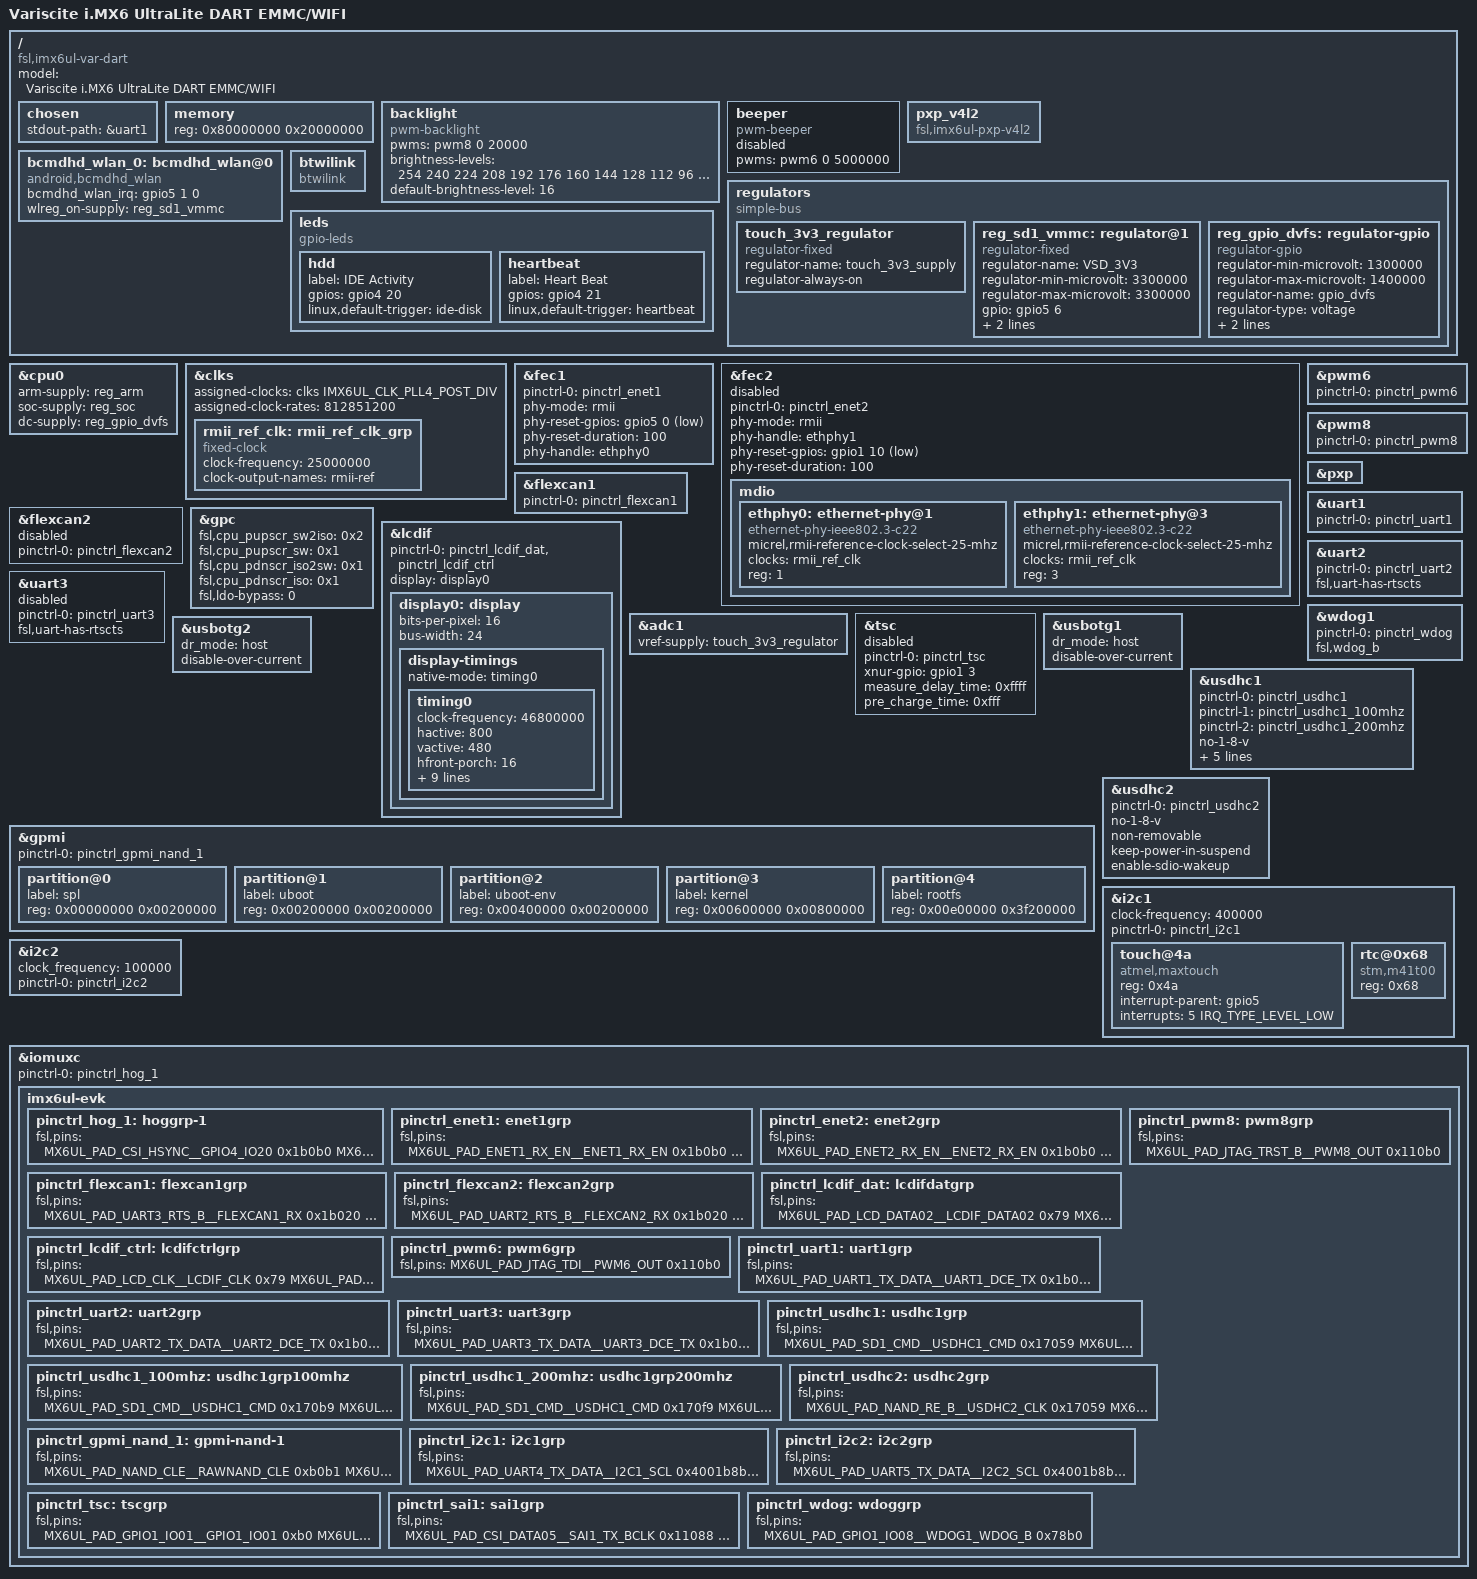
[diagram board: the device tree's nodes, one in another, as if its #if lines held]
/*
 * Copyright (C) 2015 Freescale Semiconductor, Inc.
 *
 * Copyright (C) 2015-2016 Variscite Ltd. - http://www.variscite.com
 *
 * This program is free software; you can redistribute it and/or modify
 * it under the terms of the GNU General Public License version 2 as
 * published by the Free Software Foundation.
 */
/* #define WIFI */
/* #define EMMC */
/* #define  NAND  */
/dts-v1/;

#include <dt-bindings/input/input.h>
#include "imx6ul.dtsi"

/ {
#ifdef NAND
#ifdef WIFI
	model = "Variscite i.MX6 UltraLite DART NAND/WIFI";
#else
	model = "Variscite i.MX6 UltraLite DART NAND/SD";
#endif
#endif
#ifdef EMMC
#ifdef WIFI
	model = "Variscite i.MX6 UltraLite DART EMMC/WIFI";
#else
	model = "Variscite i.MX6 UltraLite DART EMMC/SD";
#endif
#endif
	compatible = "fsl,imx6ul-var-dart", "fsl,imx6ul";

	chosen {
		stdout-path = &uart1;
	};

	memory {
		reg = <0x80000000 0x20000000>;
	};

	backlight {
		compatible = "pwm-backlight";
		pwms = <&pwm8 0 20000>;
		brightness-levels = <254 240 224 208 192 176 160 144 128 112 96 80 64 48 32 16 0>;
		default-brightness-level = <16>;
		status = "okay";
	};

	beeper {
		compatible = "pwm-beeper";
		pwms = <&pwm6 0 5000000>;
		status = "disabled";
	};

	pxp_v4l2 {
		compatible = "fsl,imx6ul-pxp-v4l2", "fsl,imx6sx-pxp-v4l2", "fsl,imx6sl-pxp-v4l2";
		status = "okay";
	};

	regulators {
		compatible = "simple-bus";
		#address-cells = <1>;
		#size-cells = <0>;

		touch_3v3_regulator: touch_3v3_regulator {
			compatible = "regulator-fixed";
			regulator-name = "touch_3v3_supply";
			regulator-always-on;
			status = "okay";
		};

#ifdef WIFI
/* force VMMC1 to always on so BT can operate independently of Wi-Fi */
		reg_sd1_vmmc: regulator@1 {
			compatible = "regulator-fixed";
			regulator-name = "VSD_3V3";
			regulator-min-microvolt = <3300000>;
			regulator-max-microvolt = <3300000>;
			gpio = <&gpio5 6 GPIO_ACTIVE_HIGH>;	/* WL_REG_ON: SNVS_TAMPER1 (gpio5_6) */
			enable-active-high;
			regulator-always-on;
		};

#endif
		reg_gpio_dvfs: regulator-gpio {
			compatible = "regulator-gpio";
			regulator-min-microvolt = <1300000>;
			regulator-max-microvolt = <1400000>;
			regulator-name = "gpio_dvfs";
			regulator-type = "voltage";
			gpios = <&gpio4 13 GPIO_ACTIVE_HIGH>;
			states = <1300000 0x1 1400000 0x0>;
		};
	};

#ifdef WIFI

	/* define hook for BCMDHD driver.   */
	/* Include WL_HOST_WAKE and WL_REG_ON GPIO's. */
	bcmdhd_wlan_0: bcmdhd_wlan@0 {
		compatible = "android,bcmdhd_wlan";
		/* WL_HOST_WAKE: ENET2_RX_ER (gpio5_01) */
		bcmdhd_wlan_irq = <&gpio5 1 0>;
		wlreg_on-supply = <&reg_sd1_vmmc>;
	};

	btwilink {
		compatible = "btwilink";
	};

#endif

	leds {
		compatible = "gpio-leds";
		hdd {
			label = "IDE Activity";
			gpios = <&gpio4 20 0>;
			linux,default-trigger = "ide-disk";
		};

		heartbeat {
			label = "Heart Beat";
			gpios = <&gpio4 21 0>;
			linux,default-trigger = "heartbeat";
		};
	};
};

&cpu0 {
	arm-supply = <&reg_arm>;
	soc-supply = <&reg_soc>;
	dc-supply = <&reg_gpio_dvfs>;
};

&clks {
	/* ref_clk for micrel ethernet phy */
	rmii_ref_clk: rmii_ref_clk_grp {
		compatible = "fixed-clock";
		#clock-cells = <0>;
		clock-frequency = <25000000>;
		clock-output-names = "rmii-ref";
	};
};

&clks {
	assigned-clocks = <&clks IMX6UL_CLK_PLL4_POST_DIV>;
	assigned-clock-rates = <812851200>;
};

&fec1 {
	pinctrl-names = "default";
	pinctrl-0 = <&pinctrl_enet1>;
	phy-mode = "rmii";
	phy-reset-gpios=<&gpio5 0 1>;
	phy-reset-duration=<100>;
	phy-handle = <&ethphy0>;
	status = "okay";
};

&fec2 {
	pinctrl-names = "default";
	pinctrl-0 = <&pinctrl_enet2>;
	phy-mode = "rmii";
	phy-handle = <&ethphy1>;
	phy-reset-gpios=<&gpio1 10 1>;
	phy-reset-duration=<100>;
	status = "disabled";
	mdio {
		#address-cells = <1>;
		#size-cells = <0>;

		ethphy0: ethernet-phy@1 {
			compatible = "ethernet-phy-ieee802.3-c22";
			micrel,rmii-reference-clock-select-25-mhz;
			clocks = <&rmii_ref_clk>;
			clock-names = "rmii-ref";
			reg = <1>;
		};

		ethphy1: ethernet-phy@3 {
			compatible = "ethernet-phy-ieee802.3-c22";
			micrel,rmii-reference-clock-select-25-mhz;
			clocks = <&rmii_ref_clk>;
			clock-names = "rmii-ref";
			reg = <3>;
		};
	};
};

&flexcan1 {
	pinctrl-names = "default";
	pinctrl-0 = <&pinctrl_flexcan1>;
	status = "okay";
};

&flexcan2 {
	pinctrl-names = "default";
	pinctrl-0 = <&pinctrl_flexcan2>;
	status = "disabled";
};

&gpc {
	fsl,cpu_pupscr_sw2iso = <0x2>;
	fsl,cpu_pupscr_sw = <0x1>;
	fsl,cpu_pdnscr_iso2sw = <0x1>;
	fsl,cpu_pdnscr_iso = <0x1>;
	fsl,ldo-bypass = <0>; /* DCDC, ldo-enable */
};

&lcdif {
	pinctrl-names = "default";
	pinctrl-0 = <&pinctrl_lcdif_dat
		     &pinctrl_lcdif_ctrl>;
	display = <&display0>;
	status = "okay";

	display0: display {
		bits-per-pixel = <16>;
		bus-width = <24>;

		display-timings {
			native-mode = <&timing0>;
			timing0: timing0 {
				clock-frequency =<46800000>;
				hactive = <800>;
				vactive = <480>;
				hfront-porch = <16>;
				hback-porch = <46>;
				hsync-len = <2>;
				vback-porch = <23>;
				vfront-porch = <7>;
				vsync-len = <2>;
				hsync-active = <0>;
				vsync-active = <0>;
				de-active = <1>;
				pixelclk-active = <0>;
			};
		};
	};
};

&pwm6 {
	pinctrl-names = "default";
	pinctrl-0 = <&pinctrl_pwm6>;
	status = "okay";
};

&pwm8 {
	pinctrl-names = "default";
	pinctrl-0 = <&pinctrl_pwm8>;
	status = "okay";
};

&pxp {
	status = "okay";
};

&adc1 {
	vref-supply = <&touch_3v3_regulator>;
	status = "okay";
};

&tsc {
	pinctrl-names = "default";
	pinctrl-0 = <&pinctrl_tsc>;
	xnur-gpio = <&gpio1 3 0>;
	measure_delay_time = <0xffff>;
	pre_charge_time = <0xfff>;
	status = "disabled";
};

/* Console Uart */
&uart1 {
	pinctrl-names = "default";
	pinctrl-0 = <&pinctrl_uart1>;
	status = "okay";
};

/* Bluetooth Uart */
&uart2 {
	pinctrl-names = "default";
	pinctrl-0 = <&pinctrl_uart2>;
	fsl,uart-has-rtscts;
	status = "okay";
};

/* ttymxc2 UART */
&uart3 {
	pinctrl-names = "default";
	pinctrl-0 = <&pinctrl_uart3>;
	fsl,uart-has-rtscts;
	status = "disabled";
};

&wdog1 {
	pinctrl-names = "default";
	pinctrl-0 = <&pinctrl_wdog>;
	fsl,wdog_b;
};

&usbotg1 {
	dr_mode = "host";
	disable-over-current;
	status = "okay";
};

&usbotg2 {
	dr_mode = "host";
	disable-over-current;
	status = "okay";
};

#ifdef WIFI
/*  Wi-Fi/BT SD Card Slot Definition */
&usdhc1 {
	pinctrl-names = "default", "state_100mhz", "state_200mhz";
	pinctrl-0 = <&pinctrl_usdhc1>;
	pinctrl-1 = <&pinctrl_usdhc1_100mhz>;
	pinctrl-2 = <&pinctrl_usdhc1_200mhz>;
	no-1-8-v;
	keep-power-in-suspend;
	enable-sdio-wakeup;
	vmmc-supply = <&reg_sd1_vmmc>;
	wifi-host;			/* add hook for SD card detect mechanism */
	non-removable;
	status = "okay";
};
#else
&usdhc1 {
	pinctrl-names = "default", "state_100mhz", "state_200mhz";
	pinctrl-0 = <&pinctrl_usdhc1>;
	pinctrl-1 = <&pinctrl_usdhc1_100mhz>;
	pinctrl-2 = <&pinctrl_usdhc1_200mhz>;
	no-1-8-v;
	keep-power-in-suspend;
	enable-sdio-wakeup;
	cd-gpios = <&gpio4 19 GPIO_ACTIVE_LOW>;
	status = "okay";
};
#endif

#ifdef NAND
&gpmi {
	pinctrl-names = "default";
	pinctrl-0 = <&pinctrl_gpmi_nand_1>;
	status = "okay";

	partition@0 {
		label = "spl";
		reg = <0x00000000 0x00200000>;
	};

	partition@1 {
		label = "uboot";
		reg = <0x00200000 0x00200000>;
	};

	partition@2 {
		label = "uboot-env";
		reg = <0x00400000 0x00200000>;
	};

	partition@3 {
		label = "kernel";
		reg = <0x00600000 0x00800000>;
	};

	partition@4 {
		label = "rootfs";
		reg = <0x00e00000 0x3f200000>;
	};
};

&usdhc2 {
	status = "disabled";
};
#endif

#ifdef EMMC
&usdhc2 {
	pinctrl-names = "default";
	pinctrl-0 = <&pinctrl_usdhc2>;
	no-1-8-v;
	non-removable;
	keep-power-in-suspend;
	enable-sdio-wakeup;
	status = "okay";
};
#endif

&i2c1 {
	clock-frequency = <400000>;
	pinctrl-names = "default";
	pinctrl-0 = <&pinctrl_i2c1>;
	status = "okay";

	/* Atmel mxt640t Touchcontroller */
	touch@4a {
                 	compatible = "atmel,maxtouch";
                 	reg = <0x4a>;
		 	interrupt-parent = <&gpio5>;
		 	interrupts = <5 IRQ_TYPE_LEVEL_LOW>;
       		};

	/* ST M41T00S RTC module */
        rtc@0x68 {
                 compatible = "stm,m41t00";
                 reg = <0x68>;
	};

};

&i2c2 {
	clock_frequency = <100000>;
	pinctrl-names = "default";
	pinctrl-0 = <&pinctrl_i2c2>;
	status = "okay";

};

&iomuxc {
	pinctrl-names = "default";
	pinctrl-0 = <&pinctrl_hog_1>;
	imx6ul-evk {
		pinctrl_hog_1: hoggrp-1 {
			fsl,pins = <
				MX6UL_PAD_CSI_HSYNC__GPIO4_IO20		0x1b0b0	/* LED 1 */
				MX6UL_PAD_CSI_DATA00__GPIO4_IO21	0x1b0b0	/* LED 2 */
				MX6UL_PAD_GPIO1_IO07__ENET2_MDC		0x1b0b0
				MX6UL_PAD_GPIO1_IO06__ENET2_MDIO	0x1b0b0
				MX6UL_PAD_SNVS_TAMPER4__GPIO5_IO04	0x1b0b0	/* BT Enable */
				MX6UL_PAD_SNVS_TAMPER0__GPIO5_IO00	0x1b0b0
				MX6UL_PAD_SNVS_TAMPER5__GPIO5_IO05 	0x1b0b0
				MX6UL_PAD_GPIO1_IO00__GPT1_CAPTURE1	0x1b0b0 /* ROTORCODESIGNAL */
				MX6UL_PAD_GPIO1_IO05__GPIO1_IO05	0x1b0b0 /* SENSE_PWR_IN */
				MX6UL_PAD_CSI_DATA01__GPIO4_IO22	0x1b0b0 /* HW_VARIANT_3 */
			>;
		};

		pinctrl_enet1: enet1grp {
			fsl,pins = <
				MX6UL_PAD_ENET1_RX_EN__ENET1_RX_EN	0x1b0b0
				MX6UL_PAD_ENET1_RX_ER__ENET1_RX_ER	0x1b0b0
				MX6UL_PAD_ENET1_RX_DATA0__ENET1_RDATA00	0x1b0b0
				MX6UL_PAD_ENET1_RX_DATA1__ENET1_RDATA01	0x1b0b0
				MX6UL_PAD_ENET1_TX_EN__ENET1_TX_EN	0x1b0b0
				MX6UL_PAD_ENET1_TX_DATA0__ENET1_TDATA00	0x1b0b0
				MX6UL_PAD_ENET1_TX_DATA1__ENET1_TDATA01	0x1b0b0
				MX6UL_PAD_ENET1_TX_CLK__ENET1_REF_CLK1	0x4001b031
			>;
		};

		pinctrl_enet2: enet2grp {
			fsl,pins = <
				MX6UL_PAD_ENET2_RX_EN__ENET2_RX_EN	0x1b0b0
				MX6UL_PAD_ENET2_RX_ER__ENET2_RX_ER	0x1b0b0
				MX6UL_PAD_ENET2_RX_DATA0__ENET2_RDATA00	0x1b0b0
				MX6UL_PAD_ENET2_RX_DATA1__ENET2_RDATA01	0x1b0b0
				MX6UL_PAD_ENET2_TX_EN__ENET2_TX_EN	0x1b0b0
				MX6UL_PAD_ENET2_TX_DATA0__ENET2_TDATA00	0x1b0b0
				MX6UL_PAD_ENET2_TX_DATA1__ENET2_TDATA01	0x1b0b0
				MX6UL_PAD_ENET2_TX_CLK__ENET2_REF_CLK2	0x4001b031
				MX6UL_PAD_JTAG_MOD__GPIO1_IO10		0x1b0b0
			>;
		};

		pinctrl_flexcan1: flexcan1grp{
			fsl,pins = <
				MX6UL_PAD_UART3_RTS_B__FLEXCAN1_RX	0x1b020
				MX6UL_PAD_UART3_CTS_B__FLEXCAN1_TX	0x1b020
			>;
		};

		pinctrl_flexcan2: flexcan2grp{
			fsl,pins = <
				MX6UL_PAD_UART2_RTS_B__FLEXCAN2_RX	0x1b020
				MX6UL_PAD_UART2_CTS_B__FLEXCAN2_TX	0x1b020
			>;
		};

		pinctrl_lcdif_dat: lcdifdatgrp {
			fsl,pins = <
				MX6UL_PAD_LCD_DATA02__LCDIF_DATA02	0x79
				MX6UL_PAD_LCD_DATA03__LCDIF_DATA03	0x79
				MX6UL_PAD_LCD_DATA04__LCDIF_DATA04	0x79
				MX6UL_PAD_LCD_DATA05__LCDIF_DATA05	0x79
				MX6UL_PAD_LCD_DATA06__LCDIF_DATA06	0x79
				MX6UL_PAD_LCD_DATA07__LCDIF_DATA07	0x79
				MX6UL_PAD_LCD_DATA10__LCDIF_DATA10	0x79
				MX6UL_PAD_LCD_DATA11__LCDIF_DATA11	0x79
				MX6UL_PAD_LCD_DATA12__LCDIF_DATA12	0x79
				MX6UL_PAD_LCD_DATA13__LCDIF_DATA13	0x79
				MX6UL_PAD_LCD_DATA14__LCDIF_DATA14	0x79
				MX6UL_PAD_LCD_DATA15__LCDIF_DATA15	0x79
				MX6UL_PAD_LCD_DATA18__LCDIF_DATA18	0x79
				MX6UL_PAD_LCD_DATA19__LCDIF_DATA19	0x79
				MX6UL_PAD_LCD_DATA20__LCDIF_DATA20	0x79
				MX6UL_PAD_LCD_DATA21__LCDIF_DATA21	0x79
				MX6UL_PAD_LCD_DATA22__LCDIF_DATA22	0x79
				MX6UL_PAD_LCD_DATA23__LCDIF_DATA23	0x79
			>;
		};

		pinctrl_lcdif_ctrl: lcdifctrlgrp {
			fsl,pins = <
				MX6UL_PAD_LCD_CLK__LCDIF_CLK		0x79
				MX6UL_PAD_LCD_ENABLE__LCDIF_ENABLE	0x79
			>;
		};

		pinctrl_pwm6: pwm6grp {
			fsl,pins = <
				MX6UL_PAD_JTAG_TDI__PWM6_OUT		0x110b0
			>;
		};

		pinctrl_pwm8: pwm8grp {
			fsl,pins = <
				MX6UL_PAD_JTAG_TRST_B__PWM8_OUT		0x110b0
			>;
		};

		pinctrl_uart1: uart1grp {
			fsl,pins = <
				MX6UL_PAD_UART1_TX_DATA__UART1_DCE_TX	0x1b0b1
				MX6UL_PAD_UART1_RX_DATA__UART1_DCE_RX	0x1b0b1
			>;
		};

		pinctrl_uart2: uart2grp {
			fsl,pins = <
				MX6UL_PAD_UART2_TX_DATA__UART2_DCE_TX	0x1b0b1
				MX6UL_PAD_UART2_RX_DATA__UART2_DCE_RX	0x1b0b1
				MX6UL_PAD_UART2_CTS_B__UART2_DCE_CTS	0x1b0b1
				MX6UL_PAD_UART2_RTS_B__UART2_DCE_RTS	0x1b0b1
			>;
		};

		pinctrl_uart3: uart3grp {
			fsl,pins = <
				MX6UL_PAD_UART3_TX_DATA__UART3_DCE_TX	0x1b0b1
				MX6UL_PAD_UART3_RX_DATA__UART3_DCE_RX	0x1b0b1
				MX6UL_PAD_UART3_CTS_B__UART3_DCE_CTS	0x1b0b1
				MX6UL_PAD_UART3_RTS_B__UART3_DCE_RTS	0x1b0b1
			>;
		};

		pinctrl_usdhc1: usdhc1grp {
			fsl,pins = <
				MX6UL_PAD_SD1_CMD__USDHC1_CMD		0x17059
				MX6UL_PAD_SD1_CLK__USDHC1_CLK		0x17059
				MX6UL_PAD_SD1_DATA0__USDHC1_DATA0	0x17059
				MX6UL_PAD_SD1_DATA1__USDHC1_DATA1	0x17059
				MX6UL_PAD_SD1_DATA2__USDHC1_DATA2	0x17059
				MX6UL_PAD_SD1_DATA3__USDHC1_DATA3	0x17059
				MX6UL_PAD_CSI_VSYNC__GPIO4_IO19		0x1b0b1	/* SD card detect */
				MX6UL_PAD_SNVS_TAMPER6__GPIO5_IO06	0x03029	/* WLAN enable */
				MX6UL_PAD_GPIO1_IO03__REF_CLK_32K	0x03029	/* WLAN Slow Clock */
			>;
		};

		pinctrl_usdhc1_100mhz: usdhc1grp100mhz {
			fsl,pins = <
				MX6UL_PAD_SD1_CMD__USDHC1_CMD		0x170b9
				MX6UL_PAD_SD1_CLK__USDHC1_CLK		0x100b9
				MX6UL_PAD_SD1_DATA0__USDHC1_DATA0	0x170b9
				MX6UL_PAD_SD1_DATA1__USDHC1_DATA1	0x170b9
				MX6UL_PAD_SD1_DATA2__USDHC1_DATA2	0x170b9
				MX6UL_PAD_SD1_DATA3__USDHC1_DATA3	0x170b9
				MX6UL_PAD_CSI_VSYNC__GPIO4_IO19		0x1b0b1	/* SD card detect */
				MX6UL_PAD_SNVS_TAMPER6__GPIO5_IO06	0x03029	/* WLAN enable */
				MX6UL_PAD_GPIO1_IO03__REF_CLK_32K	0x03029	/* WLAN Slow Clock */
			>;
		};

		pinctrl_usdhc1_200mhz: usdhc1grp200mhz {
			fsl,pins = <
				MX6UL_PAD_SD1_CMD__USDHC1_CMD		0x170f9
				MX6UL_PAD_SD1_CLK__USDHC1_CLK		0x100f9
				MX6UL_PAD_SD1_DATA0__USDHC1_DATA0	0x170f9
				MX6UL_PAD_SD1_DATA1__USDHC1_DATA1	0x170f9
				MX6UL_PAD_SD1_DATA2__USDHC1_DATA2	0x170f9
				MX6UL_PAD_SD1_DATA3__USDHC1_DATA3	0x170f9
				MX6UL_PAD_CSI_VSYNC__GPIO4_IO19		0x1b0b1	/* SD card detect */
				MX6UL_PAD_SNVS_TAMPER6__GPIO5_IO06	0x03029	/* WLAN enable */
				MX6UL_PAD_GPIO1_IO03__REF_CLK_32K	0x03029	/* WLAN Slow Clock */
			>;
		};
#ifdef EMMC
		pinctrl_usdhc2: usdhc2grp {
			fsl,pins = <
				MX6UL_PAD_NAND_RE_B__USDHC2_CLK		0x17059
				MX6UL_PAD_NAND_WE_B__USDHC2_CMD		0x17059
				MX6UL_PAD_NAND_DATA00__USDHC2_DATA0	0x17059
				MX6UL_PAD_NAND_DATA01__USDHC2_DATA1	0x17059
				MX6UL_PAD_NAND_DATA02__USDHC2_DATA2	0x17059
				MX6UL_PAD_NAND_DATA03__USDHC2_DATA3	0x17059
			>;
		};
#endif
#ifdef NAND
		pinctrl_gpmi_nand_1: gpmi-nand-1 {
			fsl,pins = <
				MX6UL_PAD_NAND_CLE__RAWNAND_CLE		0xb0b1
				MX6UL_PAD_NAND_ALE__RAWNAND_ALE		0xb0b1
				MX6UL_PAD_NAND_WP_B__RAWNAND_WP_B	0xb0b1
				MX6UL_PAD_NAND_READY_B__RAWNAND_READY_B	0xb000
				MX6UL_PAD_NAND_CE0_B__RAWNAND_CE0_B	0xb0b1
				MX6UL_PAD_NAND_CE1_B__RAWNAND_CE1_B	0xb0b1
				MX6UL_PAD_NAND_RE_B__RAWNAND_RE_B	0xb0b1
				MX6UL_PAD_NAND_WE_B__RAWNAND_WE_B	0xb0b1
				MX6UL_PAD_NAND_DATA00__RAWNAND_DATA00	0xb0b1
				MX6UL_PAD_NAND_DATA01__RAWNAND_DATA01	0xb0b1
				MX6UL_PAD_NAND_DATA02__RAWNAND_DATA02	0xb0b1
				MX6UL_PAD_NAND_DATA03__RAWNAND_DATA03	0xb0b1
				MX6UL_PAD_NAND_DATA04__RAWNAND_DATA04	0xb0b1
				MX6UL_PAD_NAND_DATA05__RAWNAND_DATA05	0xb0b1
				MX6UL_PAD_NAND_DATA06__RAWNAND_DATA06	0xb0b1
				MX6UL_PAD_NAND_DATA07__RAWNAND_DATA07	0xb0b1
			>;
		};
#endif

		pinctrl_i2c1: i2c1grp {
			fsl,pins = <
				MX6UL_PAD_UART4_TX_DATA__I2C1_SCL	0x4001b8b0
				MX6UL_PAD_UART4_RX_DATA__I2C1_SDA	0x4001b8b0
			>;
		};

		pinctrl_i2c2: i2c2grp {
			fsl,pins = <
				MX6UL_PAD_UART5_TX_DATA__I2C2_SCL	0x4001b8b0
				MX6UL_PAD_UART5_RX_DATA__I2C2_SDA	0x4001b8b0
			>;
		};

		pinctrl_tsc: tscgrp {
			fsl,pins = <
				MX6UL_PAD_GPIO1_IO01__GPIO1_IO01	0xb0
				MX6UL_PAD_GPIO1_IO02__GPIO1_IO02	0xb0
				MX6UL_PAD_GPIO1_IO03__GPIO1_IO03	0xb0
				MX6UL_PAD_GPIO1_IO04__GPIO1_IO04	0xb0
			>;
		};

		pinctrl_sai1: sai1grp {
			fsl,pins = <
				MX6UL_PAD_CSI_DATA05__SAI1_TX_BCLK	0x11088
				MX6UL_PAD_CSI_DATA04__SAI1_TX_SYNC	0x17088
				MX6UL_PAD_CSI_DATA06__SAI1_RX_DATA	0x11088
				MX6UL_PAD_CSI_DATA07__SAI1_TX_DATA	0x11088
			>;
		};

		pinctrl_wdog: wdoggrp {
			fsl,pins = <
				MX6UL_PAD_GPIO1_IO08__WDOG1_WDOG_B	0x78b0
			>;
		};
	};
};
